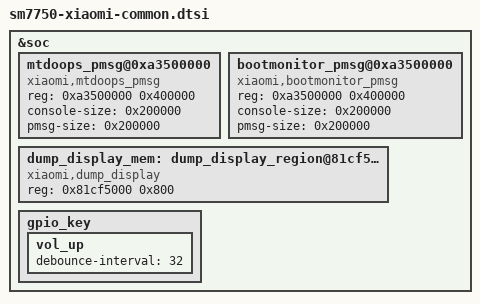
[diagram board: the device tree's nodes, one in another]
#include "kera-qrd.dtsi"
&soc {
	mtdoops_pmsg@0xa3500000 {
		compatible = "xiaomi,mtdoops_pmsg";
		reg = <0xa3500000 0x400000>;
		console-size = <0x200000>;
		pmsg-size = <0x200000>;
	};

	bootmonitor_pmsg@0xa3500000 {
		compatible = "xiaomi,bootmonitor_pmsg";
		reg = <0xa3500000 0x400000>;
		console-size = <0x200000>;
		pmsg-size = <0x200000>;
	};

	dump_display_mem: dump_display_region@81cf5000 {
		compatible = "xiaomi,dump_display";
		reg = <0x81cf5000 0x800>;
	};

	gpio_key {
		vol_up {
			debounce-interval = <32>;
		};
	};
};
